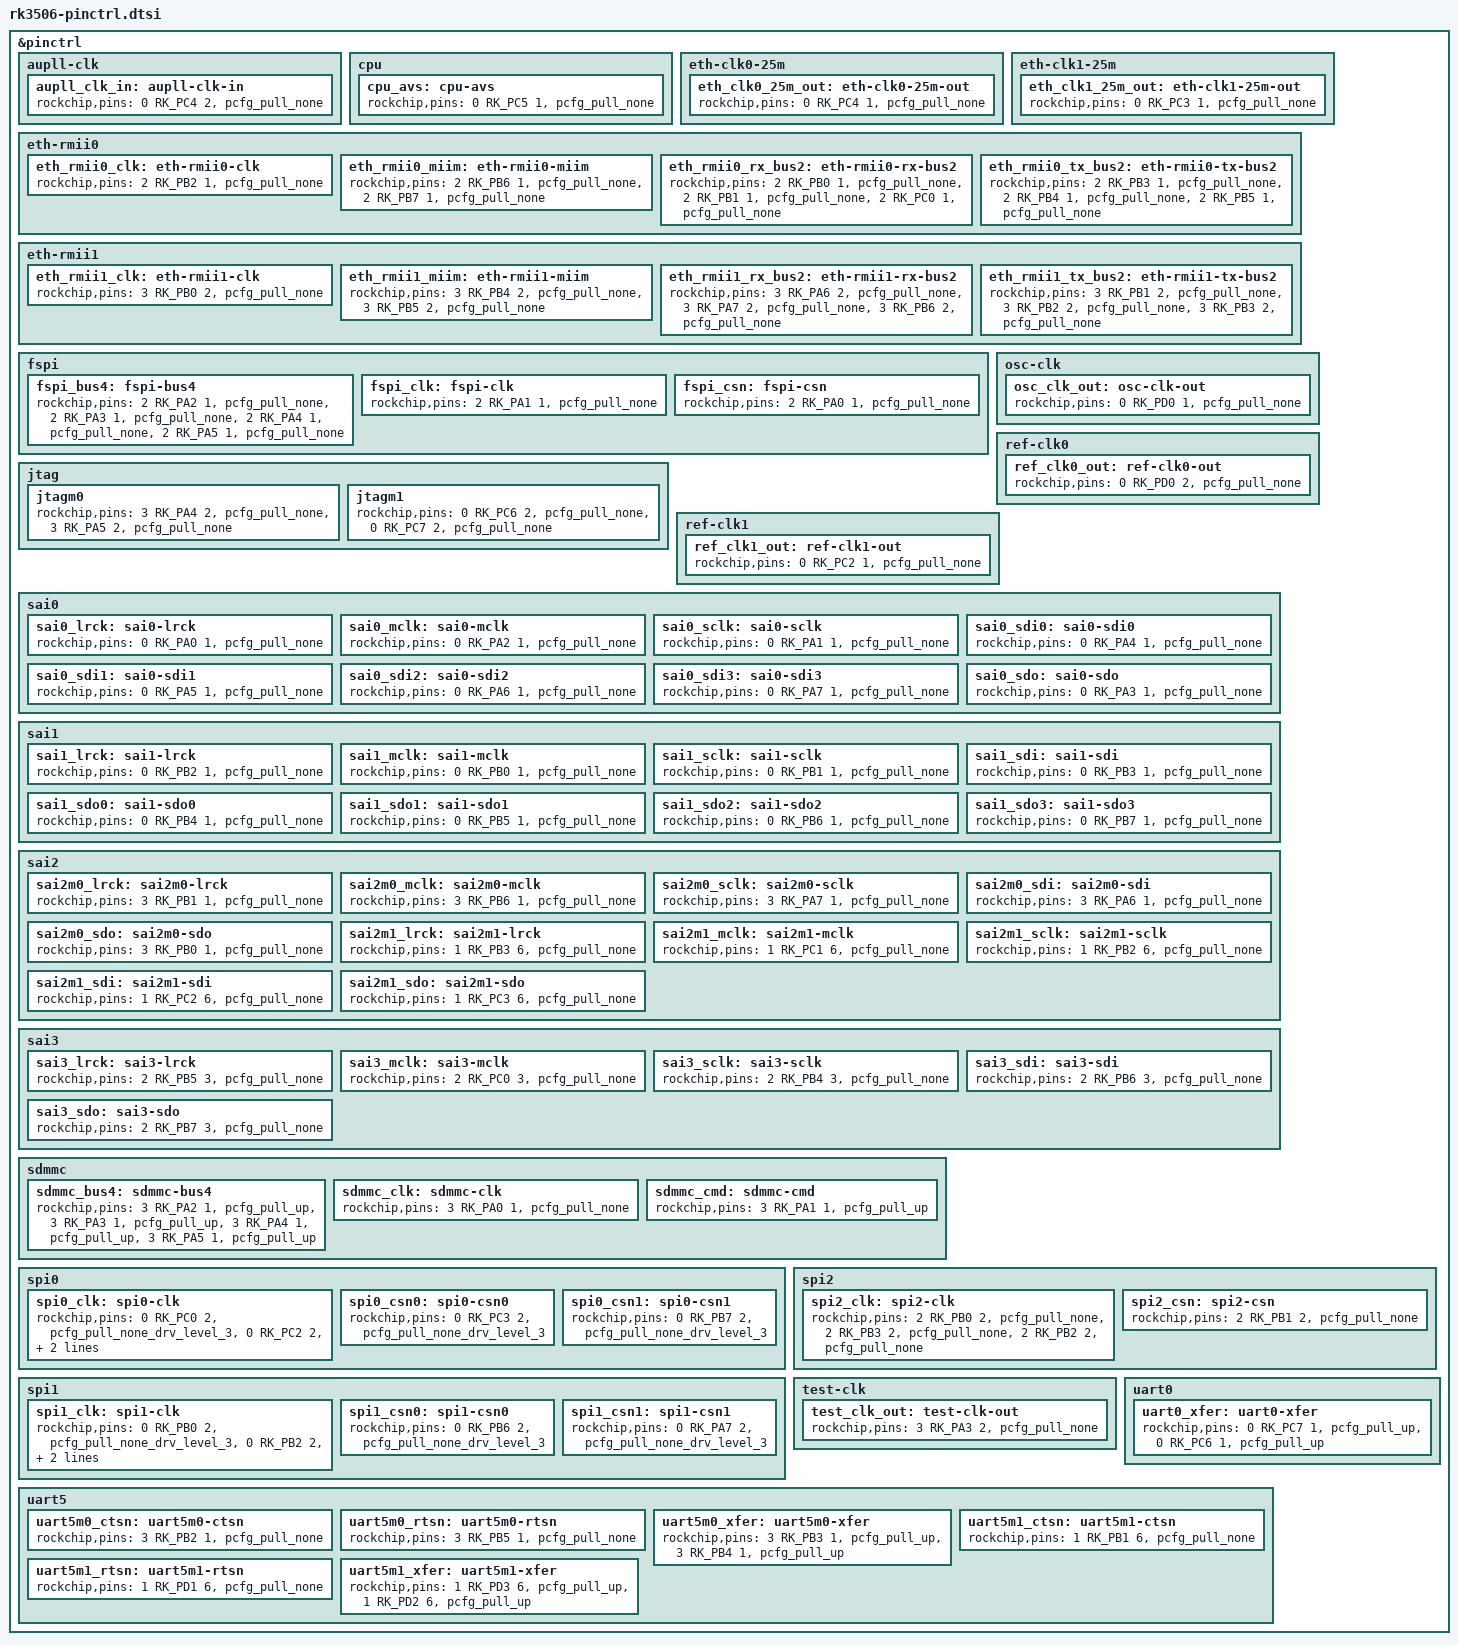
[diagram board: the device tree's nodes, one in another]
// SPDX-License-Identifier: (GPL-2.0+ OR MIT)

#include <dt-bindings/pinctrl/rockchip.h>
#include <arm64/rockchip/rockchip-pinconf.dtsi>

&pinctrl {
	aupll-clk {
		/omit-if-no-ref/
		aupll_clk_in: aupll-clk-in {
			rockchip,pins =
				/* aupll_clk_in */
				<0 RK_PC4 2 &pcfg_pull_none>;
		};
	};

	cpu {
		/omit-if-no-ref/
		cpu_avs: cpu-avs {
			rockchip,pins =
				/* cpu_avs */
				<0 RK_PC5 1 &pcfg_pull_none>;
		};
	};

	eth-clk0-25m {
		/omit-if-no-ref/
		eth_clk0_25m_out: eth-clk0-25m-out {
			rockchip,pins =
				/* eth_clk0_25m_out */
				<0 RK_PC4 1 &pcfg_pull_none>;
		};
	};

	eth-clk1-25m {
		/omit-if-no-ref/
		eth_clk1_25m_out: eth-clk1-25m-out {
			rockchip,pins =
				/* eth_clk1_25m_out */
				<0 RK_PC3 1 &pcfg_pull_none>;
		};
	};

	eth-rmii0 {
		/omit-if-no-ref/
		eth_rmii0_clk: eth-rmii0-clk {
			rockchip,pins =
				/* eth_rmii0_clk */
				<2 RK_PB2 1 &pcfg_pull_none>;
		};

		/omit-if-no-ref/
		eth_rmii0_miim: eth-rmii0-miim {
			rockchip,pins =
				/* eth_rmii0_mdc */
				<2 RK_PB6 1 &pcfg_pull_none>,
				/* eth_rmii0_mdio */
				<2 RK_PB7 1 &pcfg_pull_none>;
		};

		/omit-if-no-ref/
		eth_rmii0_rx_bus2: eth-rmii0-rx-bus2 {
			rockchip,pins =
				/* eth_rmii0_rxd0 */
				<2 RK_PB0 1 &pcfg_pull_none>,
				/* eth_rmii0_rxd1 */
				<2 RK_PB1 1 &pcfg_pull_none>,
				/* eth_rmii0_rxdvcrs */
				<2 RK_PC0 1 &pcfg_pull_none>;
		};

		/omit-if-no-ref/
		eth_rmii0_tx_bus2: eth-rmii0-tx-bus2 {
			rockchip,pins =
				/* eth_rmii0_txd0 */
				<2 RK_PB3 1 &pcfg_pull_none>,
				/* eth_rmii0_txd1 */
				<2 RK_PB4 1 &pcfg_pull_none>,
				/* eth_rmii0_txen */
				<2 RK_PB5 1 &pcfg_pull_none>;
		};
	};

	eth-rmii1 {
		/omit-if-no-ref/
		eth_rmii1_clk: eth-rmii1-clk {
			rockchip,pins =
				/* eth_rmii1_clk */
				<3 RK_PB0 2 &pcfg_pull_none>;
		};

		/omit-if-no-ref/
		eth_rmii1_miim: eth-rmii1-miim {
			rockchip,pins =
				/* eth_rmii1_mdc */
				<3 RK_PB4 2 &pcfg_pull_none>,
				/* eth_rmii1_mdio */
				<3 RK_PB5 2 &pcfg_pull_none>;
		};

		/omit-if-no-ref/
		eth_rmii1_rx_bus2: eth-rmii1-rx-bus2 {
			rockchip,pins =
				/* eth_rmii1_rxd0 */
				<3 RK_PA6 2 &pcfg_pull_none>,
				/* eth_rmii1_rxd1 */
				<3 RK_PA7 2 &pcfg_pull_none>,
				/* eth_rmii1_rxdvcrs */
				<3 RK_PB6 2 &pcfg_pull_none>;
		};

		/omit-if-no-ref/
		eth_rmii1_tx_bus2: eth-rmii1-tx-bus2 {
			rockchip,pins =
				/* eth_rmii1_txd0 */
				<3 RK_PB1 2 &pcfg_pull_none>,
				/* eth_rmii1_txd1 */
				<3 RK_PB2 2 &pcfg_pull_none>,
				/* eth_rmii1_txen */
				<3 RK_PB3 2 &pcfg_pull_none>;
		};
	};

	fspi {
		/omit-if-no-ref/
		fspi_bus4: fspi-bus4 {
			rockchip,pins =
				/* fspi_d0 */
				<2 RK_PA2 1 &pcfg_pull_none>,
				/* fspi_d1 */
				<2 RK_PA3 1 &pcfg_pull_none>,
				/* fspi_d2 */
				<2 RK_PA4 1 &pcfg_pull_none>,
				/* fspi_d3 */
				<2 RK_PA5 1 &pcfg_pull_none>;
		};

		/omit-if-no-ref/
		fspi_clk: fspi-clk {
			rockchip,pins =
				/* fspi_clk */
				<2 RK_PA1 1 &pcfg_pull_none>;
		};

		/omit-if-no-ref/
		fspi_csn: fspi-csn {
			rockchip,pins =
				/* fspi_csn */
				<2 RK_PA0 1 &pcfg_pull_none>;
		};
	};

	jtag {
		/omit-if-no-ref/
		jtagm0: jtagm0 {
			rockchip,pins =
				/* jtag_tck_m0 */
				<3 RK_PA4 2 &pcfg_pull_none>,
				/* jtag_tms_m0 */
				<3 RK_PA5 2 &pcfg_pull_none>;
		};

		/omit-if-no-ref/
		jtagm1: jtagm1 {
			rockchip,pins =
				/* jtag_tck_m1 */
				<0 RK_PC6 2 &pcfg_pull_none>,
				/* jtag_tms_m1 */
				<0 RK_PC7 2 &pcfg_pull_none>;
		};
	};

	osc-clk {
		/omit-if-no-ref/
		osc_clk_out: osc-clk-out {
			rockchip,pins =
				/* osc_clk_out */
				<0 RK_PD0 1 &pcfg_pull_none>;
		};
	};

	ref-clk0 {
		/omit-if-no-ref/
		ref_clk0_out: ref-clk0-out {
			rockchip,pins =
				/* ref_clk0_out */
				<0 RK_PD0 2 &pcfg_pull_none>;
		};
	};

	ref-clk1 {
		/omit-if-no-ref/
		ref_clk1_out: ref-clk1-out {
			rockchip,pins =
				/* ref_clk1_out */
				<0 RK_PC2 1 &pcfg_pull_none>;
		};
	};

	sai0 {
		/omit-if-no-ref/
		sai0_lrck: sai0-lrck {
			rockchip,pins =
				/* sai0_lrck */
				<0 RK_PA0 1 &pcfg_pull_none>;
		};

		/omit-if-no-ref/
		sai0_mclk: sai0-mclk {
			rockchip,pins =
				/* sai0_mclk */
				<0 RK_PA2 1 &pcfg_pull_none>;
		};

		/omit-if-no-ref/
		sai0_sclk: sai0-sclk {
			rockchip,pins =
				/* sai0_sclk */
				<0 RK_PA1 1 &pcfg_pull_none>;
		};

		/omit-if-no-ref/
		sai0_sdi0: sai0-sdi0 {
			rockchip,pins =
				/* sai0_sdi0 */
				<0 RK_PA4 1 &pcfg_pull_none>;
		};

		/omit-if-no-ref/
		sai0_sdi1: sai0-sdi1 {
			rockchip,pins =
				/* sai0_sdi1 */
				<0 RK_PA5 1 &pcfg_pull_none>;
		};

		/omit-if-no-ref/
		sai0_sdi2: sai0-sdi2 {
			rockchip,pins =
				/* sai0_sdi2 */
				<0 RK_PA6 1 &pcfg_pull_none>;
		};

		/omit-if-no-ref/
		sai0_sdi3: sai0-sdi3 {
			rockchip,pins =
				/* sai0_sdi3 */
				<0 RK_PA7 1 &pcfg_pull_none>;
		};

		/omit-if-no-ref/
		sai0_sdo: sai0-sdo {
			rockchip,pins =
				/* sai0_sdo */
				<0 RK_PA3 1 &pcfg_pull_none>;
		};
	};

	sai1 {
		/omit-if-no-ref/
		sai1_lrck: sai1-lrck {
			rockchip,pins =
				/* sai1_lrck */
				<0 RK_PB2 1 &pcfg_pull_none>;
		};

		/omit-if-no-ref/
		sai1_mclk: sai1-mclk {
			rockchip,pins =
				/* sai1_mclk */
				<0 RK_PB0 1 &pcfg_pull_none>;
		};

		/omit-if-no-ref/
		sai1_sclk: sai1-sclk {
			rockchip,pins =
				/* sai1_sclk */
				<0 RK_PB1 1 &pcfg_pull_none>;
		};

		/omit-if-no-ref/
		sai1_sdi: sai1-sdi {
			rockchip,pins =
				/* sai1_sdi */
				<0 RK_PB3 1 &pcfg_pull_none>;
		};

		/omit-if-no-ref/
		sai1_sdo0: sai1-sdo0 {
			rockchip,pins =
				/* sai1_sdo0 */
				<0 RK_PB4 1 &pcfg_pull_none>;
		};

		/omit-if-no-ref/
		sai1_sdo1: sai1-sdo1 {
			rockchip,pins =
				/* sai1_sdo1 */
				<0 RK_PB5 1 &pcfg_pull_none>;
		};

		/omit-if-no-ref/
		sai1_sdo2: sai1-sdo2 {
			rockchip,pins =
				/* sai1_sdo2 */
				<0 RK_PB6 1 &pcfg_pull_none>;
		};

		/omit-if-no-ref/
		sai1_sdo3: sai1-sdo3 {
			rockchip,pins =
				/* sai1_sdo3 */
				<0 RK_PB7 1 &pcfg_pull_none>;
		};
	};

	sai2 {
		/omit-if-no-ref/
		sai2m0_lrck: sai2m0-lrck {
			rockchip,pins =
				/* sai2_lrck_m0 */
				<3 RK_PB1 1 &pcfg_pull_none>;
		};

		/omit-if-no-ref/
		sai2m0_mclk: sai2m0-mclk {
			rockchip,pins =
				/* sai2_mclk_m0 */
				<3 RK_PB6 1 &pcfg_pull_none>;
		};

		/omit-if-no-ref/
		sai2m0_sclk: sai2m0-sclk {
			rockchip,pins =
				/* sai2_sclk_m0 */
				<3 RK_PA7 1 &pcfg_pull_none>;
		};

		/omit-if-no-ref/
		sai2m0_sdi: sai2m0-sdi {
			rockchip,pins =
				/* sai2m0_sdi */
				<3 RK_PA6 1 &pcfg_pull_none>;
		};

		/omit-if-no-ref/
		sai2m0_sdo: sai2m0-sdo {
			rockchip,pins =
				/* sai2m0_sdo */
				<3 RK_PB0 1 &pcfg_pull_none>;
		};

		/omit-if-no-ref/
		sai2m1_lrck: sai2m1-lrck {
			rockchip,pins =
				/* sai2_lrck_m1 */
				<1 RK_PB3 6 &pcfg_pull_none>;
		};

		/omit-if-no-ref/
		sai2m1_mclk: sai2m1-mclk {
			rockchip,pins =
				/* sai2_mclk_m1 */
				<1 RK_PC1 6 &pcfg_pull_none>;
		};

		/omit-if-no-ref/
		sai2m1_sclk: sai2m1-sclk {
			rockchip,pins =
				/* sai2_sclk_m1 */
				<1 RK_PB2 6 &pcfg_pull_none>;
		};

		/omit-if-no-ref/
		sai2m1_sdi: sai2m1-sdi {
			rockchip,pins =
				/* sai2m1_sdi */
				<1 RK_PC2 6 &pcfg_pull_none>;
		};

		/omit-if-no-ref/
		sai2m1_sdo: sai2m1-sdo {
			rockchip,pins =
				/* sai2m1_sdo */
				<1 RK_PC3 6 &pcfg_pull_none>;
		};
	};

	sai3 {
		/omit-if-no-ref/
		sai3_lrck: sai3-lrck {
			rockchip,pins =
				/* sai3_lrck */
				<2 RK_PB5 3 &pcfg_pull_none>;
		};

		/omit-if-no-ref/
		sai3_mclk: sai3-mclk {
			rockchip,pins =
				/* sai3_mclk */
				<2 RK_PC0 3 &pcfg_pull_none>;
		};

		/omit-if-no-ref/
		sai3_sclk: sai3-sclk {
			rockchip,pins =
				/* sai3_sclk */
				<2 RK_PB4 3 &pcfg_pull_none>;
		};

		/omit-if-no-ref/
		sai3_sdi: sai3-sdi {
			rockchip,pins =
				/* sai3_sdi */
				<2 RK_PB6 3 &pcfg_pull_none>;
		};

		/omit-if-no-ref/
		sai3_sdo: sai3-sdo {
			rockchip,pins =
				/* sai3_sdo */
				<2 RK_PB7 3 &pcfg_pull_none>;
		};
	};

	sdmmc {
		/omit-if-no-ref/
		sdmmc_bus4: sdmmc-bus4 {
			rockchip,pins =
				/* sdmmc_d0 */
				<3 RK_PA2 1 &pcfg_pull_up>,
				/* sdmmc_d1 */
				<3 RK_PA3 1 &pcfg_pull_up>,
				/* sdmmc_d2 */
				<3 RK_PA4 1 &pcfg_pull_up>,
				/* sdmmc_d3 */
				<3 RK_PA5 1 &pcfg_pull_up>;
		};

		/omit-if-no-ref/
		sdmmc_clk: sdmmc-clk {
			rockchip,pins =
				/* sdmmc_clk */
				<3 RK_PA0 1 &pcfg_pull_none>;
		};

		/omit-if-no-ref/
		sdmmc_cmd: sdmmc-cmd {
			rockchip,pins =
				/* sdmmc_cmd */
				<3 RK_PA1 1 &pcfg_pull_up>;
		};
	};

	spi0 {
		/omit-if-no-ref/
		spi0_clk: spi0-clk {
			rockchip,pins =
				/* spi0_clk */
				<0 RK_PC0 2 &pcfg_pull_none_drv_level_3>,
				/* spi0_miso */
				<0 RK_PC2 2 &pcfg_pull_none_drv_level_3>,
				/* spi0_mosi */
				<0 RK_PC1 2 &pcfg_pull_none_drv_level_3>;
		};

		/omit-if-no-ref/
		spi0_csn0: spi0-csn0 {
			rockchip,pins =
				/* spi0_csn0 */
				<0 RK_PC3 2 &pcfg_pull_none_drv_level_3>;
		};

		/omit-if-no-ref/
		spi0_csn1: spi0-csn1 {
			rockchip,pins =
				/* spi0_csn1 */
				<0 RK_PB7 2 &pcfg_pull_none_drv_level_3>;
		};
	};

	spi1 {
		/omit-if-no-ref/
		spi1_clk: spi1-clk {
			rockchip,pins =
				/* spi1_clk */
				<0 RK_PB0 2 &pcfg_pull_none_drv_level_3>,
				/* spi1_miso */
				<0 RK_PB2 2 &pcfg_pull_none_drv_level_3>,
				/* spi1_mosi */
				<0 RK_PB1 2 &pcfg_pull_none_drv_level_3>;
		};

		/omit-if-no-ref/
		spi1_csn0: spi1-csn0 {
			rockchip,pins =
				/* spi1_csn0 */
				<0 RK_PB6 2 &pcfg_pull_none_drv_level_3>;
		};

		/omit-if-no-ref/
		spi1_csn1: spi1-csn1 {
			rockchip,pins =
				/* spi1_csn1 */
				<0 RK_PA7 2 &pcfg_pull_none_drv_level_3>;
		};
	};

	spi2 {
		/omit-if-no-ref/
		spi2_clk: spi2-clk {
			rockchip,pins =
				/* spi2_clk */
				<2 RK_PB0 2 &pcfg_pull_none>,
				/* spi2_miso */
				<2 RK_PB3 2 &pcfg_pull_none>,
				/* spi2_mosi */
				<2 RK_PB2 2 &pcfg_pull_none>;
		};

		/omit-if-no-ref/
		spi2_csn: spi2-csn {
			rockchip,pins =
				/* spi2_csn */
				<2 RK_PB1 2 &pcfg_pull_none>;
		};
	};

	test-clk {
		/omit-if-no-ref/
		test_clk_out: test-clk-out {
			rockchip,pins =
				/* test_clk_out */
				<3 RK_PA3 2 &pcfg_pull_none>;
		};
	};

	uart0 {
		/omit-if-no-ref/
		uart0_xfer: uart0-xfer {
			rockchip,pins =
				/* uart0_rx */
				<0 RK_PC7 1 &pcfg_pull_up>,
				/* uart0_tx */
				<0 RK_PC6 1 &pcfg_pull_up>;
		};
	};

	uart5 {
		/omit-if-no-ref/
		uart5m0_ctsn: uart5m0-ctsn {
			rockchip,pins =
				/* uart5m0_ctsn */
				<3 RK_PB2 1 &pcfg_pull_none>;
		};

		/omit-if-no-ref/
		uart5m0_rtsn: uart5m0-rtsn {
			rockchip,pins =
				/* uart5m0_rtsn */
				<3 RK_PB5 1 &pcfg_pull_none>;
		};

		/omit-if-no-ref/
		uart5m0_xfer: uart5m0-xfer {
			rockchip,pins =
				/* uart5_rx_m0 */
				<3 RK_PB3 1 &pcfg_pull_up>,
				/* uart5_tx_m0 */
				<3 RK_PB4 1 &pcfg_pull_up>;
		};

		/omit-if-no-ref/
		uart5m1_ctsn: uart5m1-ctsn {
			rockchip,pins =
				/* uart5m1_ctsn */
				<1 RK_PB1 6 &pcfg_pull_none>;
		};

		/omit-if-no-ref/
		uart5m1_rtsn: uart5m1-rtsn {
			rockchip,pins =
				/* uart5m1_rtsn */
				<1 RK_PD1 6 &pcfg_pull_none>;
		};

		/omit-if-no-ref/
		uart5m1_xfer: uart5m1-xfer {
			rockchip,pins =
				/* uart5_rx_m1 */
				<1 RK_PD3 6 &pcfg_pull_up>,
				/* uart5_tx_m1 */
				<1 RK_PD2 6 &pcfg_pull_up>;
		};
	};
};
